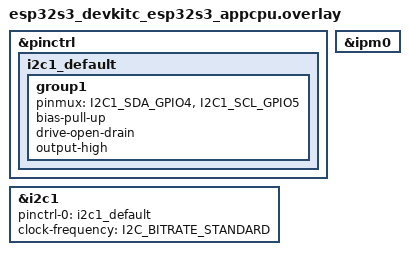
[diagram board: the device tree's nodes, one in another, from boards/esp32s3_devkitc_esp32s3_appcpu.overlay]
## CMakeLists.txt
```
# APP_CPU (core 1) image = display core.
cmake_minimum_required(VERSION 3.20.0)

find_package(Zephyr REQUIRED HINTS $ENV{ZEPHYR_BASE})
project(ld2402_display_appcpu)

target_include_directories(app PRIVATE ../common src)
target_sources(app PRIVATE
	src/display_main.c
	src/radar_display_ssd1306.c
	src/ssd1306_display.c
	../common/radar_link_ipm.c
)
```

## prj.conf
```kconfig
# APP_CPU (core 1) - display core: SSD1306 (raw I2C driver) on I2C1 + IPM rx
# Same base config as the hardware-verified multi-sensor AMP Lab 01 core1 image.
# Note: APP_CPU has no console UART, printk/LOG output is not visible.

CONFIG_I2C=y
CONFIG_GPIO=y

CONFIG_IPM=y
CONFIG_ESP32_SOFT_IPM=y

# ssd1306_display.c uses LOG_MODULE_REGISTER
CONFIG_LOG=y
CONFIG_LOG_MODE_IMMEDIATE=y

CONFIG_MAIN_STACK_SIZE=4096
```

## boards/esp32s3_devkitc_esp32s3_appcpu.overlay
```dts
/*
 * APP_CPU (display core) devicetree overlay.
 *
 * Same I2C1 setup as the hardware-verified multi-sensor AMP Lab 01:
 *   GPIO4 = I2C1 SDA, GPIO5 = I2C1 SCL (not strapping / USB-JTAG pins)
 * The SSD1306 is NOT declared as a devicetree node: the raw driver
 * (src/ssd1306_display.c) probes 0x3C then 0x3D at runtime.
 */
#include <dt-bindings/pinctrl/esp32s3-pinctrl.h>
#include <zephyr/dt-bindings/i2c/i2c.h>

&pinctrl {
	i2c1_default: i2c1_default {
		group1 {
			pinmux = <I2C1_SDA_GPIO4>, <I2C1_SCL_GPIO5>;
			bias-pull-up;
			drive-open-drain;
			output-high;
		};
	};
};

&i2c1 {
	status = "okay";
	pinctrl-0 = <&i2c1_default>;
	pinctrl-names = "default";
	clock-frequency = <I2C_BITRATE_STANDARD>;
};

&ipm0 {
	status = "okay";
};
```

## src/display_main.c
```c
/*
 * display_main.c - display core application (identical on ESP32-S3 and SR110).
 *
 *   ESP32-S3 : runs on APP_CPU (core 1)
 *   SR110    : runs on Cortex-M55
 *
 * Flow:
 *   1. Init SSD1306 through CFB, show a waiting screen.
 *   2. Register the link rx callback (ISR -> k_msgq).
 *   3. Loop: take the newest message, track link health, redraw on change.
 */
#include <zephyr/kernel.h>
#include <zephyr/sys/printk.h>

#include "radar_display.h"
#include "radar_link.h"
#include "radar_msg.h"

#define UI_TICK_MS        200
#define LINK_TIMEOUT_MS   3000 /* sensor core sends at least every 500 ms */

K_MSGQ_DEFINE(radar_msgq, sizeof(struct radar_msg), 8, 4);

/* Drain the queue and keep only the newest message. */
static bool take_newest(struct radar_msg *out, k_timeout_t timeout)
{
	if (k_msgq_get(&radar_msgq, out, timeout) != 0) {
		return false;
	}
	while (k_msgq_get(&radar_msgq, out, K_NO_WAIT) == 0) {
	}
	return true;
}

int main(void)
{
	struct radar_msg latest = {0};
	bool have_msg = false;
	bool prev_link_ok = false;
	int64_t last_rx_ms = 0;

	printk("\n=== LD2402 AMP: display core (%s) ===\n", CONFIG_BOARD_TARGET);

	if (radar_display_init() != 0) {
		return 0;
	}
	radar_display_show_text("LINK: WAIT", "LD2402 AMP");

	if (radar_link_rx_init(&radar_msgq) != 0) {
		radar_display_show_text("LINK: FAIL", "IPC INIT ERR");
		return 0;
	}

	while (true) {
		struct radar_msg msg;
		bool got_msg = take_newest(&msg, K_MSEC(UI_TICK_MS));
		bool link_ok;

		if (got_msg) {
			latest = msg;
			have_msg = true;
			last_rx_ms = k_uptime_get();
		}

		link_ok = have_msg && (k_uptime_get() - last_rx_ms) < LINK_TIMEOUT_MS;

		if (link_ok != prev_link_ok) {
			printk("[DISPLAY] link %s (last seq=%u)\n", link_ok ? "UP" : "DOWN",
			       latest.seq);
		}

		if (got_msg || link_ok != prev_link_ok) {
			radar_display_render(&latest, link_ok);
		}
		prev_link_ok = link_ok;
	}

	return 0;
}
```

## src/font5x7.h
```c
/*
 * font5x7.h
 *
 * Minimal original 5x7 dot-matrix font for the SSD1306 text
 * renderer used across this multi-sensor lab series. Only the
 * characters this series actually prints (labels, digits,
 * units, punctuation) are defined; anything else falls back
 * to a blank glyph in font5x7_lookup().
 *
 * Layout: 5 columns per glyph, column-major, bit0 = top row,
 * 7 rows tall (fits an 8px-tall character cell with 1px gap).
 */

#ifndef FONT5X7_H_
#define FONT5X7_H_

#include <stdint.h>
#include <stddef.h>
#include <zephyr/sys/util.h> /* ARRAY_SIZE */

#define FONT5X7_WIDTH  5
#define FONT5X7_HEIGHT 7

static const uint8_t FONT_SPACE[FONT5X7_WIDTH] = {0x00, 0x00, 0x00, 0x00, 0x00};
static const uint8_t FONT_BANG[FONT5X7_WIDTH] = {0x00, 0x5F, 0x5F, 0x00, 0x00};
static const uint8_t FONT_PERCENT[FONT5X7_WIDTH] = {0x21, 0x10, 0x0C, 0x02, 0x21};
static const uint8_t FONT_DASH[FONT5X7_WIDTH] = {0x08, 0x08, 0x08, 0x08, 0x08};
static const uint8_t FONT_DOT[FONT5X7_WIDTH] = {0x00, 0x60, 0x60, 0x00, 0x00};
static const uint8_t FONT_0[FONT5X7_WIDTH] = {0x3E, 0x51, 0x49, 0x45, 0x3E};
static const uint8_t FONT_1[FONT5X7_WIDTH] = {0x00, 0x42, 0x7F, 0x40, 0x00};
static const uint8_t FONT_2[FONT5X7_WIDTH] = {0x42, 0x61, 0x51, 0x49, 0x46};
static const uint8_t FONT_3[FONT5X7_WIDTH] = {0x22, 0x41, 0x49, 0x49, 0x36};
static const uint8_t FONT_4[FONT5X7_WIDTH] = {0x18, 0x14, 0x12, 0x7F, 0x10};
static const uint8_t FONT_5[FONT5X7_WIDTH] = {0x27, 0x45, 0x45, 0x45, 0x39};
static const uint8_t FONT_6[FONT5X7_WIDTH] = {0x3C, 0x4A, 0x49, 0x49, 0x30};
static const uint8_t FONT_7[FONT5X7_WIDTH] = {0x01, 0x71, 0x09, 0x05, 0x03};
static const uint8_t FONT_8[FONT5X7_WIDTH] = {0x36, 0x49, 0x49, 0x49, 0x36};
static const uint8_t FONT_9[FONT5X7_WIDTH] = {0x06, 0x49, 0x49, 0x29, 0x1E};
static const uint8_t FONT_COLON[FONT5X7_WIDTH] = {0x00, 0x36, 0x36, 0x00, 0x00};
static const uint8_t FONT_A[FONT5X7_WIDTH] = {0x7C, 0x12, 0x11, 0x12, 0x7C};
static const uint8_t FONT_B[FONT5X7_WIDTH] = {0x7F, 0x49, 0x49, 0x49, 0x36};
static const uint8_t FONT_C[FONT5X7_WIDTH] = {0x3E, 0x41, 0x41, 0x41, 0x41};
static const uint8_t FONT_D[FONT5X7_WIDTH] = {0x7F, 0x41, 0x41, 0x41, 0x3E};
static const uint8_t FONT_E[FONT5X7_WIDTH] = {0x7F, 0x49, 0x49, 0x49, 0x41};
static const uint8_t FONT_F[FONT5X7_WIDTH] = {0x7F, 0x09, 0x09, 0x09, 0x01};
static const uint8_t FONT_G[FONT5X7_WIDTH] = {0x3E, 0x41, 0x49, 0x49, 0x79};
static const uint8_t FONT_H[FONT5X7_WIDTH] = {0x7F, 0x08, 0x08, 0x08, 0x7F};
static const uint8_t FONT_I[FONT5X7_WIDTH] = {0x41, 0x41, 0x7F, 0x41, 0x41};
static const uint8_t FONT_L[FONT5X7_WIDTH] = {0x7F, 0x40, 0x40, 0x40, 0x40};
static const uint8_t FONT_M[FONT5X7_WIDTH] = {0x7F, 0x02, 0x04, 0x02, 0x7F};
static const uint8_t FONT_N[FONT5X7_WIDTH] = {0x7F, 0x02, 0x04, 0x08, 0x7F};
static const uint8_t FONT_O[FONT5X7_WIDTH] = {0x3E, 0x41, 0x41, 0x41, 0x3E};
static const uint8_t FONT_P[FONT5X7_WIDTH] = {0x7F, 0x09, 0x09, 0x09, 0x06};
static const uint8_t FONT_R[FONT5X7_WIDTH] = {0x7F, 0x09, 0x19, 0x29, 0x46};
static const uint8_t FONT_S[FONT5X7_WIDTH] = {0x46, 0x49, 0x49, 0x49, 0x31};
static const uint8_t FONT_T[FONT5X7_WIDTH] = {0x01, 0x01, 0x7F, 0x01, 0x01};
static const uint8_t FONT_U[FONT5X7_WIDTH] = {0x3F, 0x40, 0x40, 0x40, 0x3F};
static const uint8_t FONT_V[FONT5X7_WIDTH] = {0x1F, 0x20, 0x40, 0x20, 0x1F};
static const uint8_t FONT_W[FONT5X7_WIDTH] = {0x7F, 0x20, 0x18, 0x20, 0x7F};
static const uint8_t FONT_Y[FONT5X7_WIDTH] = {0x03, 0x04, 0x78, 0x04, 0x03};
static const uint8_t FONT_K[FONT5X7_WIDTH] = {0x7F, 0x08, 0x14, 0x22, 0x41};
static const uint8_t FONT_h[FONT5X7_WIDTH] = {0x7F, 0x08, 0x04, 0x04, 0x78};
static const uint8_t FONT_a[FONT5X7_WIDTH] = {0x20, 0x54, 0x54, 0x54, 0x78};

struct font5x7_entry {
	char ch;
	const uint8_t *cols;
};

/* Added for the LD2402 lab: '+', '/', 'c', 'm', 's' */
static const uint8_t FONT_PLUS[FONT5X7_WIDTH] = {0x08, 0x08, 0x3E, 0x08, 0x08};
static const uint8_t FONT_SLASH[FONT5X7_WIDTH] = {0x20, 0x10, 0x08, 0x04, 0x02};
static const uint8_t FONT_c[FONT5X7_WIDTH] = {0x38, 0x44, 0x44, 0x44, 0x20};
static const uint8_t FONT_m[FONT5X7_WIDTH] = {0x7C, 0x04, 0x18, 0x04, 0x78};
static const uint8_t FONT_s[FONT5X7_WIDTH] = {0x48, 0x54, 0x54, 0x54, 0x20};

static const struct font5x7_entry font5x7_table[] = {
	{ ' ', FONT_SPACE },
	{ '!', FONT_BANG },
	{ '%', FONT_PERCENT },
	{ '-', FONT_DASH },
	{ '.', FONT_DOT },
	{ '0', FONT_0 },
	{ '1', FONT_1 },
	{ '2', FONT_2 },
	{ '3', FONT_3 },
	{ '4', FONT_4 },
	{ '5', FONT_5 },
	{ '6', FONT_6 },
	{ '7', FONT_7 },
	{ '8', FONT_8 },
	{ '9', FONT_9 },
	{ ':', FONT_COLON },
	{ 'A', FONT_A },
	{ 'B', FONT_B },
	{ 'C', FONT_C },
	{ 'D', FONT_D },
	{ 'E', FONT_E },
	{ 'F', FONT_F },
	{ 'G', FONT_G },
	{ 'H', FONT_H },
	{ 'I', FONT_I },
	{ 'L', FONT_L },
	{ 'M', FONT_M },
	{ 'N', FONT_N },
	{ 'O', FONT_O },
	{ 'P', FONT_P },
	{ 'R', FONT_R },
	{ 'S', FONT_S },
	{ 'T', FONT_T },
	{ 'U', FONT_U },
	{ 'V', FONT_V },
	{ 'W', FONT_W },
	{ 'Y', FONT_Y },
	{ 'K', FONT_K },
	{ 'h', FONT_h },
	{ 'a', FONT_a },
	{ '+', FONT_PLUS },
	{ '/', FONT_SLASH },
	{ 'c', FONT_c },
	{ 'm', FONT_m },
	{ 's', FONT_s },
};

/* Returns the 5-byte column array for `ch`, or NULL if the
 * character isn't in the table (caller should render a blank).
 */
static inline const uint8_t *font5x7_lookup(char ch)
{
	for (size_t i = 0; i < ARRAY_SIZE(font5x7_table); i++) {
		if (font5x7_table[i].ch == ch) {
			return font5x7_table[i].cols;
		}
	}
	return NULL;
}

#endif /* FONT5X7_H_ */
```

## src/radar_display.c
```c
/*
 * radar_display.c - SSD1306 renderer for radar_msg (see radar_display.h).
 */
#include "radar_display.h"

#include <errno.h>
#include <stdio.h>
#include <zephyr/device.h>
#include <zephyr/display/cfb.h>
#include <zephyr/drivers/display.h>
#include <zephyr/kernel.h>
#include <zephyr/sys/printk.h>

#define FONT_HEIGHT_WANTED  16

#define ROW_LINK_Y      0
#define ROW_STATE_Y     16
#define MARKER_Y        32
#define BAR_TOP_Y       34
#define BAR_BOTTOM_Y    63
#define BAR_MAX_H       (BAR_BOTTOM_Y - BAR_TOP_Y + 1) /* 30 px */
#define BAR_PITCH       8                              /* 16 gates x 8 px = 128 px */
#define BAR_WIDTH       6

/*
 * Bar scaling: typical background is 10..25 dB and thresholds sit around
 * 40..60 dB (manual / field experience), so map 10..70 dB to full height.
 */
#define DB_FLOOR        10
#define DB_CEIL         70

#define GATE_SIZE_CM    70

static const struct device *const display = DEVICE_DT_GET(DT_CHOSEN(zephyr_display));

static void select_font(void)
{
	int count = cfb_get_numof_fonts(display);

	for (int idx = 0; idx < count; idx++) {
		uint8_t w;
		uint8_t h;

		if (cfb_get_font_size(display, idx, &w, &h) == 0 && h == FONT_HEIGHT_WANTED) {
			cfb_framebuffer_set_font(display, idx);
			return;
		}
	}
	cfb_framebuffer_set_font(display, 0); /* fallback: first font */
}

int radar_display_init(void)
{
	if (!device_is_ready(display)) {
		printk("[DISP] display device not ready\n");
		return -ENODEV;
	}

	if (display_blanking_off(display) != 0) {
		printk("[DISP] display_blanking_off failed\n");
	}

	if (cfb_framebuffer_init(display) != 0) {
		/* most common cause: CONFIG_HEAP_MEM_POOL_SIZE too small */
		printk("[DISP] cfb_framebuffer_init failed\n");
		return -EIO;
	}

	select_font();
	cfb_set_kerning(display, 0);
	cfb_framebuffer_clear(display, true);
	return 0;
}

void radar_display_show_text(const char *line1, const char *line2)
{
	cfb_framebuffer_clear(display, false);
	if (line1 != NULL) {
		cfb_print(display, line1, 0, ROW_LINK_Y);
	}
	if (line2 != NULL) {
		cfb_print(display, line2, 0, ROW_STATE_Y);
	}
	cfb_framebuffer_finalize(display);
}

static const char *presence_label(uint8_t presence)
{
	switch (presence) {
	case RADAR_PRESENCE_MOVING:
		return "MOVE";
	case RADAR_PRESENCE_STILL:
		return "STILL";
	default:
		return "NONE";
	}
}

static int db_to_bar_height(uint8_t db)
{
	if (db <= DB_FLOOR) {
		return 0;
	}
	if (db >= DB_CEIL) {
		return BAR_MAX_H;
	}
	return ((db - DB_FLOOR) * BAR_MAX_H) / (DB_CEIL - DB_FLOOR);
}

static void draw_vline(int x, int y_top, int y_bottom)
{
	struct cfb_position start;
	struct cfb_position end;

	start.x = x;
	start.y = y_top;
	end.x = x;
	end.y = y_bottom;
	cfb_draw_line(display, &start, &end);
}

static void draw_hline(int x_left, int x_right, int y)
{
	struct cfb_position start;
	struct cfb_position end;

	start.x = x_left;
	start.y = y;
	end.x = x_right;
	end.y = y;
	cfb_draw_line(display, &start, &end);
}

static void draw_energy_bars(const uint8_t db[RADAR_GATE_COUNT])
{
	for (int gate = 0; gate < RADAR_GATE_COUNT; gate++) {
		int h = db_to_bar_height(db[gate]);
		int x0 = gate * BAR_PITCH;

		/* 1 px baseline so empty gates are still visible */
		draw_hline(x0, x0 + BAR_WIDTH - 1, BAR_BOTTOM_Y);

		for (int x = x0; x < x0 + BAR_WIDTH && h > 0; x++) {
			draw_vline(x, BAR_BOTTOM_Y - h + 1, BAR_BOTTOM_Y);
		}
	}
}

/*
 * Direction arrow at the right end of row 2 (x 112..127, y 16..31).
 * Gate 0 (= sensor) is on the LEFT of the bar graph, so:
 *   APPROACH -> arrow points left  (toward the sensor)
 *   LEAVE    -> arrow points right (away from the sensor)
 *   STEADY   -> short horizontal bar
 */
#define ARROW_X0   112
#define ARROW_X1   127
#define ARROW_Y    23

static void draw_direction(uint8_t direction)
{
	switch (direction) {
	case RADAR_DIR_APPROACH:
		draw_hline(ARROW_X0, ARROW_X1, ARROW_Y);
		for (int i = 1; i <= 4; i++) {
			draw_vline(ARROW_X0 + i, ARROW_Y - i, ARROW_Y + i);
		}
		break;
	case RADAR_DIR_LEAVE:
		draw_hline(ARROW_X0, ARROW_X1, ARROW_Y);
		for (int i = 1; i <= 4; i++) {
			draw_vline(ARROW_X1 - i, ARROW_Y - i, ARROW_Y + i);
		}
		break;
	case RADAR_DIR_STEADY:
		draw_hline(ARROW_X0 + 4, ARROW_X1 - 4, ARROW_Y);
		break;
	default:
		break; /* unknown: draw nothing */
	}
}

static void draw_target_marker(uint16_t distance_cm)
{
	int gate = distance_cm / GATE_SIZE_CM;
	int x0;

	if (gate >= RADAR_GATE_COUNT) {
		gate = RADAR_GATE_COUNT - 1;
	}
	x0 = gate * BAR_PITCH;
	draw_hline(x0, x0 + BAR_WIDTH - 1, MARKER_Y);
}

void radar_display_render(const struct radar_msg *msg, bool link_ok)
{
	char line[16];
	bool sensor_ok = (msg->flags & RADAR_FLAG_SENSOR_OK) != 0;
	bool has_target = (msg->presence != RADAR_PRESENCE_NONE);

	cfb_framebuffer_clear(display, false);

	/* row 1: inter-core link status - always on top */
	cfb_print(display, link_ok ? "LINK: OK" : "LINK: FAIL", 0, ROW_LINK_Y);

	if (!link_ok) {
		cfb_framebuffer_finalize(display);
		return;
	}

	/* row 2: radar state */
	if (!sensor_ok) {
		snprintf(line, sizeof(line), "NO SENSOR");
	} else if (has_target) {
		snprintf(line, sizeof(line), "%-5s%4ucm", presence_label(msg->presence),
			 (unsigned int)msg->distance_cm);
	} else {
		snprintf(line, sizeof(line), "%s", presence_label(msg->presence));
	}
	cfb_print(display, line, 0, ROW_STATE_Y);
	if (sensor_ok && has_target) {
		draw_direction(msg->direction);
	}

	/* bottom: per-gate motion energy (engineering mode only) */
	if (sensor_ok && (msg->flags & RADAR_FLAG_ENERGY) != 0) {
		if (has_target) {
			draw_target_marker(msg->distance_cm);
		}
		draw_energy_bars(msg->motion_db);
	} else if (sensor_ok) {
		cfb_print(display, "ASCII MODE", 0, 40);
	}

	cfb_framebuffer_finalize(display);
}
```

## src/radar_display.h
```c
/*
 * radar_display.h - SSD1306 (128x64) renderer for radar_msg.
 *
 * Same API on both platforms, different backend:
 *   ESP32-S3 : radar_display_ssd1306.c (raw-I2C driver, 5x7 font)
 *   SR110    : radar_display.c (Zephyr solomon,ssd1306 + CFB, 10x16 font)
 */
#ifndef RADAR_DISPLAY_H_
#define RADAR_DISPLAY_H_

#include <stdbool.h>
#include "radar_msg.h"

/* Uses the devicetree chosen node "zephyr,display". */
int radar_display_init(void);

void radar_display_show_text(const char *line1, const char *line2);

void radar_display_render(const struct radar_msg *msg, bool link_ok);

#endif /* RADAR_DISPLAY_H_ */
```

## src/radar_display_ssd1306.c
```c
/*
 * radar_display_ssd1306.c - ESP32-S3 implementation of radar_display.h.
 *
 * Uses the raw-I2C SSD1306 driver (ssd1306_display.c) that was hardware-
 * verified in the multi-sensor AMP labs, NOT Zephyr's solomon,ssd1306 +
 * CFB: on ESP32-S3 the in-tree display driver splits the control byte and
 * the pixel payload into separate I2C messages, which hits the known ESP32
 * I2C driver issue and produces noise. The raw driver always sends one
 * contiguous i2c_write().
 *
 * Screen layout (5x7 font, 8 px text rows = SSD1306 pages):
 *   page 0 (y= 0.. 7)  "LINK: OK" / "LINK: FAIL"
 *   page 2 (y=16..23)  "MOVE  123cm" ... + direction arrow at x=112..127
 *   page 3 (y=24..31)  "APPROACH -96cm/s"
 *   y=32               target-gate marker
 *   y=34..63           16-gate motion energy bar graph
 */
#include "radar_display.h"

#include <errno.h>
#include <stdio.h>
#include <zephyr/device.h>
#include <zephyr/devicetree.h>
#include <zephyr/kernel.h>
#include <zephyr/sys/printk.h>

#include "ssd1306_display.h"

#define PAGE_LINK       0
#define PAGE_STATE      2
#define PAGE_TREND      3

#define MARKER_Y        32
#define BAR_TOP_Y       34
#define BAR_BOTTOM_Y    63
#define BAR_MAX_H       (BAR_BOTTOM_Y - BAR_TOP_Y + 1) /* 30 px */
#define BAR_PITCH       8                              /* 16 gates x 8 px = 128 px */
#define BAR_WIDTH       6

/* map 10..70 dB to full bar height (background ~10-25 dB) */
#define DB_FLOOR        10
#define DB_CEIL         70

#define GATE_SIZE_CM    70

/* direction arrow, vertically centered in page 2 */
#define ARROW_X0        112
#define ARROW_X1        127
#define ARROW_Y         19
#define ARROW_HEAD      3

static const struct device *const i2c_dev = DEVICE_DT_GET(DT_NODELABEL(i2c1));

int radar_display_init(void)
{
	int ret;

	if (!device_is_ready(i2c_dev)) {
		printk("[DISP] i2c1 not ready\n");
		return -ENODEV;
	}

	ret = ssd1306_display_init(i2c_dev);
	if (ret != 0) {
		printk("[DISP] SSD1306 init failed (%d)\n", ret);
	}
	return ret;
}

void radar_display_show_text(const char *line1, const char *line2)
{
	ssd1306_clear();
	if (line1 != NULL) {
		ssd1306_draw_text(PAGE_LINK, 0, line1);
	}
	if (line2 != NULL) {
		ssd1306_draw_text(PAGE_STATE, 0, line2);
	}
	ssd1306_flush();
}

static const char *presence_label(uint8_t presence)
{
	switch (presence) {
	case RADAR_PRESENCE_MOVING:
		return "MOVE";
	case RADAR_PRESENCE_STILL:
		return "STILL";
	default:
		return "NONE";
	}
}

static const char *direction_label(uint8_t direction)
{
	switch (direction) {
	case RADAR_DIR_APPROACH:
		return "APPROACH";
	case RADAR_DIR_LEAVE:
		return "LEAVE";
	case RADAR_DIR_STEADY:
		return "STEADY";
	default:
		return NULL;
	}
}

static int db_to_bar_height(uint8_t db)
{
	if (db <= DB_FLOOR) {
		return 0;
	}
	if (db >= DB_CEIL) {
		return BAR_MAX_H;
	}
	return ((db - DB_FLOOR) * BAR_MAX_H) / (DB_CEIL - DB_FLOOR);
}

static void draw_energy_bars(const uint8_t db[RADAR_GATE_COUNT])
{
	for (int gate = 0; gate < RADAR_GATE_COUNT; gate++) {
		int h = db_to_bar_height(db[gate]);
		int x0 = gate * BAR_PITCH;

		/* 1 px baseline so empty gates are still visible */
		ssd1306_draw_hline(x0, x0 + BAR_WIDTH - 1, BAR_BOTTOM_Y);

		for (int x = x0; x < x0 + BAR_WIDTH && h > 0; x++) {
			ssd1306_draw_vline(x, BAR_BOTTOM_Y - h + 1, BAR_BOTTOM_Y);
		}
	}
}

static void draw_target_marker(uint16_t distance_cm)
{
	int gate = distance_cm / GATE_SIZE_CM;
	int x0;

	if (gate >= RADAR_GATE_COUNT) {
		gate = RADAR_GATE_COUNT - 1;
	}
	x0 = gate * BAR_PITCH;
	ssd1306_draw_hline(x0, x0 + BAR_WIDTH - 1, MARKER_Y);
}

/* Gate 0 (= sensor) is on the left: approach points left, leave points right. */
static void draw_direction(uint8_t direction)
{
	switch (direction) {
	case RADAR_DIR_APPROACH:
		ssd1306_draw_hline(ARROW_X0, ARROW_X1, ARROW_Y);
		for (int i = 1; i <= ARROW_HEAD; i++) {
			ssd1306_draw_vline(ARROW_X0 + i, ARROW_Y - i, ARROW_Y + i);
		}
		break;
	case RADAR_DIR_LEAVE:
		ssd1306_draw_hline(ARROW_X0, ARROW_X1, ARROW_Y);
		for (int i = 1; i <= ARROW_HEAD; i++) {
			ssd1306_draw_vline(ARROW_X1 - i, ARROW_Y - i, ARROW_Y + i);
		}
		break;
	case RADAR_DIR_STEADY:
		ssd1306_draw_hline(ARROW_X0 + 4, ARROW_X1 - 4, ARROW_Y);
		break;
	default:
		break;
	}
}

/* Outlined progress bar with a filled part, y = 44..55 */
static void draw_progress_bar(uint8_t percent)
{
	int fill = (percent * 126) / 100;

	ssd1306_draw_hline(0, 127, 44);
	ssd1306_draw_hline(0, 127, 55);
	ssd1306_draw_vline(0, 44, 55);
	ssd1306_draw_vline(127, 44, 55);
	for (int x = 1; x <= fill; x++) {
		ssd1306_draw_vline(x, 46, 53);
	}
}

/* Calibration screens (auto threshold generation on the sensor core). */
static void render_calibration(const struct radar_msg *msg)
{
	char line[24];

	switch (msg->calib_state) {
	case RADAR_CALIB_COUNTDOWN:
		ssd1306_draw_text(PAGE_STATE, 0, "AUTO THRESHOLD");
		ssd1306_draw_text(PAGE_TREND, 0, "LEAVE THE AREA");
		snprintf(line, sizeof(line), "START IN %us", (unsigned int)msg->calib_pct);
		ssd1306_draw_text(5, 0, line);
		break;
	case RADAR_CALIB_RUNNING:
		ssd1306_draw_text(PAGE_STATE, 0, "AUTO THRESHOLD");
		snprintf(line, sizeof(line), "CALIBRATING %u%%", (unsigned int)msg->calib_pct);
		ssd1306_draw_text(PAGE_TREND, 0, line);
		draw_progress_bar(msg->calib_pct);
		break;
	case RADAR_CALIB_DONE:
		ssd1306_draw_text(PAGE_STATE, 0, "CALIB DONE");
		ssd1306_draw_text(PAGE_TREND, 0, "SAVED TO RADAR");
		break;
	default:
		ssd1306_draw_text(PAGE_STATE, 0, "CALIB FAIL");
		ssd1306_draw_text(PAGE_TREND, 0, "SEE CONSOLE");
		break;
	}
}

void radar_display_render(const struct radar_msg *msg, bool link_ok)
{
	char line[24];
	bool sensor_ok = (msg->flags & RADAR_FLAG_SENSOR_OK) != 0;
	bool has_target = (msg->presence != RADAR_PRESENCE_NONE);
	const char *dir_text = direction_label(msg->direction);

	ssd1306_clear();

	/* page 0: inter-core link status - always on top */
	ssd1306_draw_text(PAGE_LINK, 0, link_ok ? "LINK: OK" : "LINK: FAIL");

	if (!link_ok) {
		ssd1306_flush();
		return;
	}

	if (msg->calib_state != RADAR_CALIB_IDLE) {
		render_calibration(msg);
		ssd1306_flush();
		return;
	}

	/* page 2: radar state */
	if (!sensor_ok) {
		snprintf(line, sizeof(line), "NO SENSOR");
	} else if (has_target) {
		snprintf(line, sizeof(line), "%-5s %4ucm", presence_label(msg->presence),
			 (unsigned int)msg->distance_cm);
	} else {
		snprintf(line, sizeof(line), "%s", presence_label(msg->presence));
	}
	ssd1306_draw_text(PAGE_STATE, 0, line);

	/* page 3 + arrow: approach / leave (needs ~0.8 s of samples) */
	if (sensor_ok && has_target && dir_text != NULL) {
		snprintf(line, sizeof(line), "%-8s %+dcm/s", dir_text, (int)msg->speed_cms);
		ssd1306_draw_text(PAGE_TREND, 0, line);
		draw_direction(msg->direction);
	}

	/* bottom: per-gate motion energy (engineering mode only) */
	if (sensor_ok && (msg->flags & RADAR_FLAG_ENERGY) != 0) {
		if (has_target) {
			draw_target_marker(msg->distance_cm);
		}
		draw_energy_bars(msg->motion_db);
	} else if (sensor_ok) {
		ssd1306_draw_text(5, 0, "ASCII MODE");
	}

	ssd1306_flush();
}
```

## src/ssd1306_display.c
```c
/*
 * ssd1306_display.c
 *
 * See ssd1306_display.h for the rationale behind driving this panel
 * with raw I2C calls instead of the in-tree display subsystem.
 */

#include "ssd1306_display.h"
#include "font5x7.h"

#include <zephyr/drivers/i2c.h>
#include <zephyr/logging/log.h>
#include <string.h>
#include <errno.h>

LOG_MODULE_REGISTER(ssd1306, LOG_LEVEL_INF);

/* Candidate 7-bit addresses; 0x3C is by far the most common on 4-pin
 * I2C SSD1306 breakout boards, 0x3D shows up on a few variants.
 */
static const uint8_t candidate_addrs[] = { 0x3C, 0x3D };

static const struct device *dev_i2c;
static uint8_t panel_addr;

/* GDDRAM mirror. Contiguous in memory (page-major), so it can be
 * pushed to the panel with a single memcpy + single I2C write.
 */
static uint8_t framebuffer[SSD1306_PAGES][SSD1306_WIDTH];

/* Standard SSD1306 128x64 init sequence (see SSD1306 datasheet,
 * section "Command Table"). Sent as ONE command stream: the control
 * byte 0x00 with the Co bit cleared tells the panel every following
 * byte is a command, so this entire array can go out as a single
 * i2c_write() alongside that one control byte.
 */
static const uint8_t init_cmds[] = {
	0xAE,       /* display off */
	0xD5, 0x80, /* clock divide ratio / oscillator frequency */
	0xA8, 0x3F, /* multiplex ratio = 64 - 1 */
	0xD3, 0x00, /* display offset = 0 */
	0x40,       /* display start line = 0 */
	0x8D, 0x14, /* charge pump enable (required for most 3.3V-only modules) */
	0x20, 0x00, /* memory addressing mode = horizontal */
	0xA1,       /* segment remap (column 127 -> SEG0) */
	0xC8,       /* COM output scan direction, remapped */
	0xDA, 0x12, /* COM pins hardware configuration */
	0x81, 0xCF, /* contrast control */
	0xD9, 0xF1, /* pre-charge period */
	0xDB, 0x40, /* VCOMH deselect level */
	0xA4,       /* resume RAM content display (not "all pixels on") */
	0xA6,       /* normal display (not inverted) */
	/* Fix the addressing window to the full panel once. In horizontal
	 * addressing mode the GDDRAM pointer auto-wraps from the last
	 * column of one page to the first column of the next, and wraps
	 * from page 7 back to page 0 after a full 1024-byte write - so
	 * this only needs to be set once, not before every flush.
	 */
	0x21, 0x00, 0x7F, /* column address range: 0..127 */
	0x22, 0x00, 0x07, /* page address range: 0..7 */
	0xAF,             /* display on */
};

static int send_cmd_stream(uint8_t addr, const uint8_t *cmds, size_t len)
{
	/* control byte (0x00 = command stream) + payload, single buffer */
	uint8_t buf[64];

	if (len + 1 > sizeof(buf)) {
		return -ENOMEM;
	}

	buf[0] = 0x00;
	memcpy(&buf[1], cmds, len);

	return i2c_write(dev_i2c, buf, len + 1, addr);
}

static int probe_panel(void)
{
	for (size_t i = 0; i < ARRAY_SIZE(candidate_addrs); i++) {
		/* A real command (display-off) doubles as the probe: a
		 * NACK from an unpopulated address returns a non-zero
		 * errno here rather than corrupting anything, since only
		 * the addressed device (if any) reacts to it.
		 */
		int ret = send_cmd_stream(candidate_addrs[i], init_cmds, 1);

		if (ret == 0) {
			panel_addr = candidate_addrs[i];
			LOG_INF("SSD1306 found at 0x%02X", panel_addr);
			return 0;
		}
	}

	LOG_ERR("SSD1306 not found at 0x3C or 0x3D");
	return -ENODEV;
}

int ssd1306_display_init(const struct device *i2c_dev)
{
	int ret;

	dev_i2c = i2c_dev;

	ret = probe_panel();
	if (ret) {
		return ret;
	}

	/* Boot stabilization delay, same convention as the OLED I2C labs
	 * earlier in this series.
	 */
	k_msleep(100);

	ret = send_cmd_stream(panel_addr, init_cmds, sizeof(init_cmds));
	if (ret) {
		LOG_ERR("SSD1306 init command stream failed: %d", ret);
		return ret;
	}

	ssd1306_clear();
	return ssd1306_flush();
}

void ssd1306_clear(void)
{
	memset(framebuffer, 0, sizeof(framebuffer));
}

void ssd1306_draw_text(uint8_t page, uint8_t col, const char *text)
{
	if (page >= SSD1306_PAGES) {
		return;
	}

	for (const char *p = text; *p != '\0'; p++) {
		if (col + FONT5X7_WIDTH > SSD1306_WIDTH) {
			break; /* clip, don't wrap */
		}

		const uint8_t *glyph = font5x7_lookup(*p);

		if (glyph != NULL) {
			memcpy(&framebuffer[page][col], glyph, FONT5X7_WIDTH);
		} else {
			memset(&framebuffer[page][col], 0, FONT5X7_WIDTH);
		}

		col += FONT5X7_WIDTH;

		/* 1px inter-character gap */
		if (col < SSD1306_WIDTH) {
			framebuffer[page][col] = 0x00;
			col += 1;
		}
	}
}

void ssd1306_set_pixel(int x, int y, bool on)
{
	uint8_t mask;

	if (x < 0 || x >= SSD1306_WIDTH || y < 0 || y >= SSD1306_HEIGHT) {
		return;
	}

	/* page-major GDDRAM: bit0 of each byte is the top row of the page */
	mask = (uint8_t)(1u << (y % 8));
	if (on) {
		framebuffer[y / 8][x] |= mask;
	} else {
		framebuffer[y / 8][x] &= (uint8_t)~mask;
	}
}

void ssd1306_draw_hline(int x0, int x1, int y)
{
	for (int x = x0; x <= x1; x++) {
		ssd1306_set_pixel(x, y, true);
	}
}

void ssd1306_draw_vline(int x, int y0, int y1)
{
	for (int y = y0; y <= y1; y++) {
		ssd1306_set_pixel(x, y, true);
	}
}

int ssd1306_flush(void)
{
	/* control byte (0x40 = data stream) + full 1024-byte framebuffer,
	 * single contiguous buffer, single i2c_write() - see the header
	 * comment for why this must never be split into two messages.
	 */
	static uint8_t tx_buf[1 + sizeof(framebuffer)];

	tx_buf[0] = 0x40;
	memcpy(&tx_buf[1], framebuffer, sizeof(framebuffer));

	return i2c_write(dev_i2c, tx_buf, sizeof(tx_buf), panel_addr);
}
```

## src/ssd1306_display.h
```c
/*
 * ssd1306_display.h
 *
 * Minimal SSD1306 128x64 I2C text display driver, written raw against
 * the I2C API instead of Zephyr's in-tree display subsystem.
 *
 * Why raw I2C and not the official `solomon,ssd1306fb` driver + CFB:
 * this series' roadmap already root-caused a confirmed ESP32 Zephyr
 * I2C driver bug where multi-segment write transactions are not
 * reliably concatenated (see Lab 02 / parked SSD1306 I2C lab notes).
 * The official display driver issues the control byte and the pixel
 * payload as separate i2c messages, which reproduces that exact bug
 * on this SoC. This driver instead always merges the control byte and
 * the payload into ONE contiguous buffer and issues a single
 * `i2c_write()`, which is the workaround this series has already
 * validated on real hardware.
 */

#ifndef SSD1306_DISPLAY_H_
#define SSD1306_DISPLAY_H_

#include <zephyr/device.h>
#include <stdint.h>
#include <stdbool.h>

#define SSD1306_WIDTH  128
#define SSD1306_HEIGHT 64
#define SSD1306_PAGES  (SSD1306_HEIGHT / 8) /* 8 pages, 8 rows each */

/* Probes 0x3C then 0x3D (write-based probing, per this series' I2C0
 * convention), runs the panel init sequence, and clears the screen.
 * Returns 0 on success, -ENODEV if neither address responds, or a
 * negative I2C errno otherwise.
 */
int ssd1306_display_init(const struct device *i2c_dev);

/* Clears the in-RAM framebuffer only. Call ssd1306_flush() to push it
 * to the panel.
 */
void ssd1306_clear(void);

/* Draws a string using the 5x7 font at character-cell granularity.
 * `page` is 0..7 (each page is one 8px text row on a 64px-tall panel).
 * `col` is the starting pixel column, 0..127. Characters not present
 * in the font table render as a blank cell. Text is clipped, not
 * wrapped, if it would run past column 127.
 */
void ssd1306_draw_text(uint8_t page, uint8_t col, const char *text);

/* Pixel primitives on the in-RAM framebuffer (added for the LD2402 lab).
 * Coordinates outside the panel are clipped.
 */
void ssd1306_set_pixel(int x, int y, bool on);
void ssd1306_draw_hline(int x0, int x1, int y);
void ssd1306_draw_vline(int x, int y0, int y1);

/* Pushes the in-RAM framebuffer to the panel as a single I2C write. */
int ssd1306_flush(void);

#endif /* SSD1306_DISPLAY_H_ */
```
